# STM32MP153 register map
File version: 1.3
CPU: CM4 r0p1, little endian, no MPU, FPU, 4 interrupt priority bits
Registers are 32-bit, read-write, reset 0x0 unless marked. A register's access mark holds for its fields unless they carry their own. Offsets are from the block's base; [hi:lo] are bit positions; {n}, {i} and the like mark numbered series.

## EXTI
Base 0x5000D000
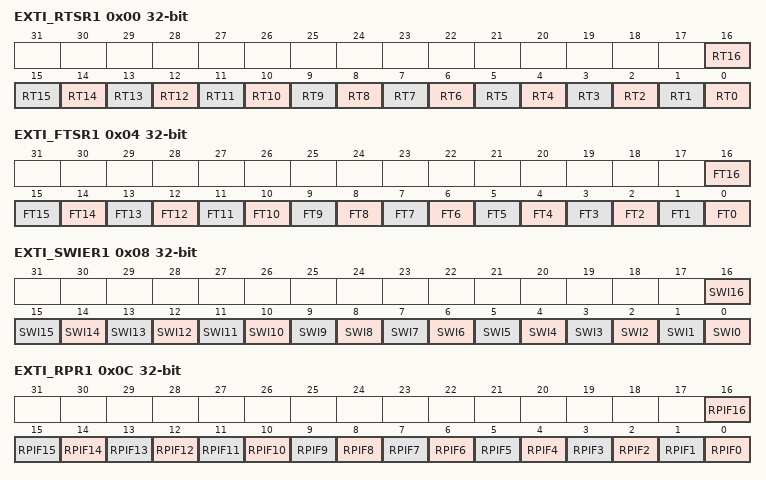
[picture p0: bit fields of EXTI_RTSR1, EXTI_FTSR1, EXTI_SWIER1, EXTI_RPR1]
0x00 EXTI_RTSR1 — Contains only register bits for configurable events.
  [n] RT{n} (n=0..16)
0x04 EXTI_FTSR1 — Contains only register bits for configurable events.
  [n] FT{n} (n=0..16)
0x08 EXTI_SWIER1 — Contains only register bits for configurable events.
  [n] SWI{n} (n=0..16)
0x0C EXTI_RPR1 — Contains only register bits for configurable events.
  [n] RPIF{n} (n=0..16)
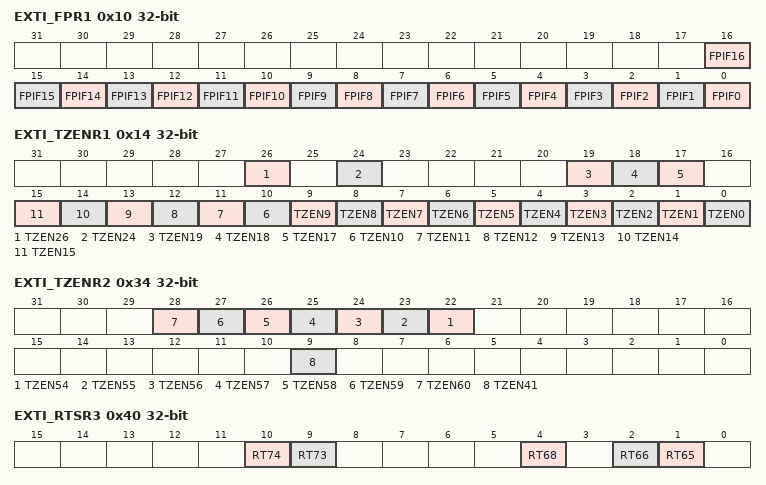
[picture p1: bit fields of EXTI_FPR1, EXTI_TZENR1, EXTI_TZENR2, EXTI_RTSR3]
0x10 EXTI_FPR1 — Contains only register bits for configurable events.
  [n] FPIF{n} (n=0..16)
0x14 EXTI_TZENR1 — This register provides TrustZone Write access security, a non-secure write access will generate a bus error. A non-secure read will return the register data. Contains only register bits for TrustZone capable Input events.
  [26] TZEN26, [24] TZEN24, [19] TZEN19, [18] TZEN18, [17] TZEN17, [n] TZEN{n} (n=0..15)
0x20 EXTI_RTSR2 — Contains only register bits for configurable events.
0x24 EXTI_FTSR2 — Contains only register bits for configurable events.
0x28 EXTI_SWIER2 — Contains only register bits for configurable events.
0x2C EXTI_RPR2 — Contains only register bits for configurable events.
0x30 EXTI_FPR2 — Contains only register bits for configurable events.
0x34 EXTI_TZENR2 — This register provides TrustZone Write access security, a non-secure write access will generate a bus error. A non-secure read will return the register data. Contains only register bits for TrustZone capable Input events.
  [n-32] TZEN{n} (n=54..60), [9] TZEN41
0x40 EXTI_RTSR3 — Contains only register bits for configurable events.
  [10] RT74, [9] RT73, [4] RT68, [2] RT66, [1] RT65
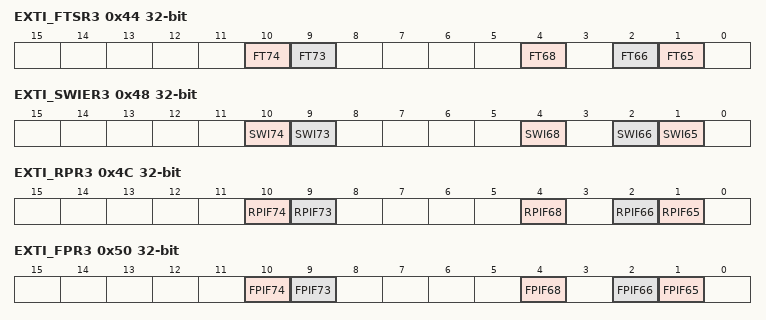
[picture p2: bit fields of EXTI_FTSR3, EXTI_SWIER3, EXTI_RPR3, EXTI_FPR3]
0x44 EXTI_FTSR3 — Contains only register bits for configurable events.
  [10] FT74, [9] FT73, [4] FT68, [2] FT66, [1] FT65
0x48 EXTI_SWIER3 — Contains only register bits for configurable events.
  [10] SWI74, [9] SWI73, [4] SWI68, [2] SWI66, [1] SWI65
0x4C EXTI_RPR3 — Contains only register bits for configurable events.
  [10] RPIF74, [9] RPIF73, [4] RPIF68, [2] RPIF66, [1] RPIF65
0x50 EXTI_FPR3 — Contains only register bits for configurable events.
  [10] FPIF74, [9] FPIF73, [4] FPIF68, [2] FPIF66, [1] FPIF65
0x54 EXTI_TZENR3 — This register provides TrustZone Write access security, a non-secure write access will generate a bus error. A non-secure read will return the register data. Contains only register bits for TrustZone capable Input events.
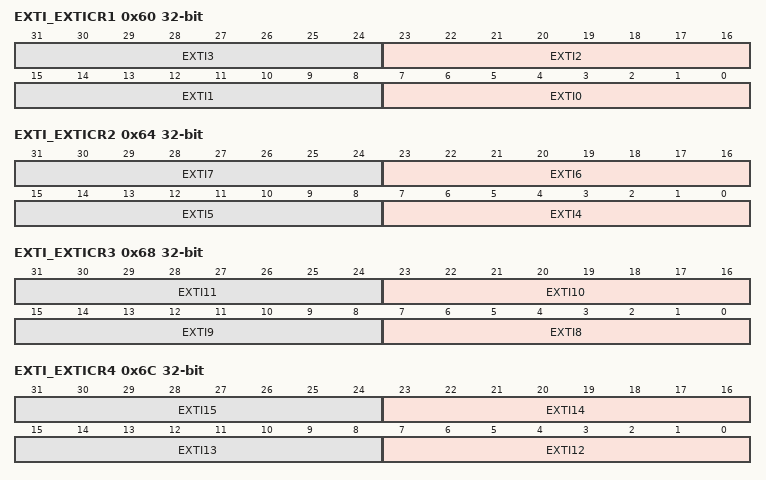
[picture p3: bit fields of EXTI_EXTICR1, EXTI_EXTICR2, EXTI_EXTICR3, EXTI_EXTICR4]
0x60 EXTI_EXTICR1 — EXTIm fields contain only the number of bits in line with the nb_ioport configuration.
  [8n+7:8n] EXTI{n} (n=0..3)
0x64 EXTI_EXTICR2 — EXTIm fields contain only the number of bits in line with the nb_ioport configuration.
  [8n-25:8n-32] EXTI{n} (n=4..7)
0x68 EXTI_EXTICR3 — EXTIm fields contain only the number of bits in line with the nb_ioport configuration.
  [8n-57:8n-64] EXTI{n} (n=8..11)
0x6C EXTI_EXTICR4 — EXTIm fields contain only the number of bits in line with the nb_ioport configuration.
  [8n-89:8n-96] EXTI{n} (n=12..15)
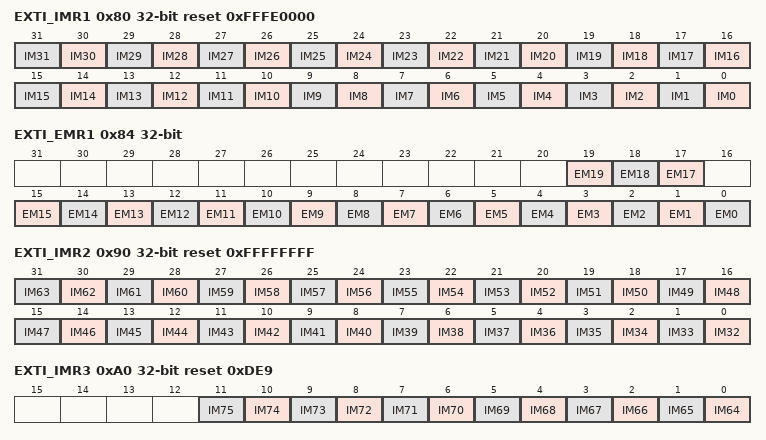
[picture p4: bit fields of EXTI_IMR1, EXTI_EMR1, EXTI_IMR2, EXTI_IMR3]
0x80 EXTI_IMR1 reset 0xFFFE0000 — Contains register bits for configurable events and Direct events.
  [n] IM{n} (n=0..31)
0x84 EXTI_EMR1 — EXTI CPU wakeup with event mask register
  [19] EM19, [18] EM18, [17] EM17, [n] EM{n} (n=0..15)
0x90 EXTI_IMR2 reset 0xFFFFFFFF — Contains register bits for configurable events and direct events.
  [n-32] IM{n} (n=32..63)
0x94 EXTI_EMR2 — EXTI CPU wakeup with event mask register
0xA0 EXTI_IMR3 reset 0xDE9 — Contains register bits for configurable events and direct events.
  [n-64] IM{n} (n=64..75)
0xA4 EXTI_EMR3 — EXTI CPU wakeup with event mask register
  [2] EM66
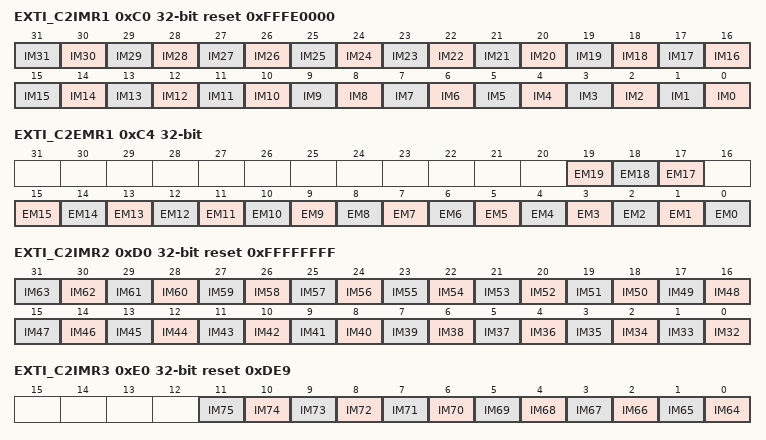
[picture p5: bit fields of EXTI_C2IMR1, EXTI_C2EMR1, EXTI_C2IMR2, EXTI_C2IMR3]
0xC0 EXTI_C2IMR1 reset 0xFFFE0000 — Contains register bits for configurable events and Direct events.
  [n] IM{n} (n=0..31)
0xC4 EXTI_C2EMR1 — EXTI CPU2 wakeup with event mask register
  [19] EM19, [18] EM18, [17] EM17, [n] EM{n} (n=0..15)
0xD0 EXTI_C2IMR2 reset 0xFFFFFFFF — Contains register bits for configurable events and direct events.
  [n-32] IM{n} (n=32..63)
0xD4 EXTI_C2EMR2 — EXTI CPU2 wakeup with event mask register
0xE0 EXTI_C2IMR3 reset 0xDE9 — Contains register bits for configurable events and direct events.
  [n-64] IM{n} (n=64..75)
0xE4 EXTI_C2EMR3 — EXTI CPU2 wakeup with event mask register
  [2] EM66
0x3C0 EXTI_HWCFGR13 ro reset 0x50EFFFF — EXTI hardware configuration register 13
  [31:0] TZ
0x3C4 EXTI_HWCFGR12 ro reset 0x50EFFFF — EXTI hardware configuration register 12
  [31:0] TZ
0x3C8 EXTI_HWCFGR11 ro reset 0x50EFFFF — EXTI hardware configuration register 11
  [31:0] TZ
0x3CC EXTI_HWCFGR10 ro — EXTI hardware configuration register 10
0x3D0 EXTI_HWCFGR9 ro — EXTI hardware configuration register 9
0x3D4 EXTI_HWCFGR8 ro — EXTI hardware configuration register 8
0x3D8 EXTI_HWCFGR7 ro reset 0xEFFFF — EXTI hardware configuration register 7
  [31:0] CPUEVENT
0x3DC EXTI_HWCFGR6 ro reset 0xEFFFF — EXTI hardware configuration register 6
  [31:0] CPUEVENT
0x3E0 EXTI_HWCFGR5 ro reset 0xEFFFF — EXTI hardware configuration register 5
  [31:0] CPUEVENT
0x3E4 EXTI_HWCFGR4 ro reset 0x1FFFF — EXTI hardware configuration register 4
  [31:0] EVENT_TRG
0x3E8 EXTI_HWCFGR3 ro reset 0x1FFFF — EXTI hardware configuration register 3
  [31:0] EVENT_TRG
0x3EC EXTI_HWCFGR2 ro reset 0x1FFFF — EXTI hardware configuration register 2
  [31:0] EVENT_TRG
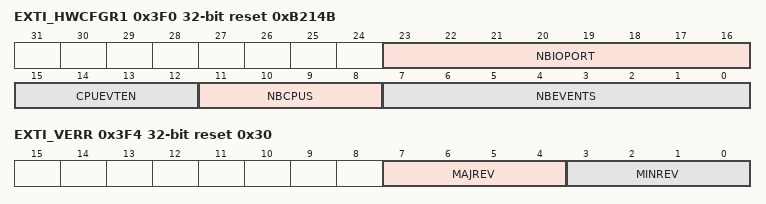
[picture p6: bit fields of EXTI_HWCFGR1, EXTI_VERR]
0x3F0 EXTI_HWCFGR1 ro reset 0xB214B — EXTI hardware configuration register 1
  [23:16] NBIOPORT, [15:12] CPUEVTEN, [11:8] NBCPUS, [7:0] NBEVENTS
0x3F4 EXTI_VERR ro reset 0x30 — EXTI IP version register
  [7:4] MAJREV, [3:0] MINREV
0x3F8 EXTI_IPIDR ro reset 0xE0001 — EXTI identification register
  [31:0] IPID
0x3FC EXTI_SIDR ro reset 0xA3C5DD01 — EXTI size ID register
  [31:0] SID
